# UART7 register map
Registers from a debugger description file.
Registers are 32-bit, access not given, no defined reset value unless marked. A register's access mark holds for its fields unless they carry their own. Addresses are absolute; registers are grouped by the start of their names; lines under a group give offsets from that group; [hi:lo] are bit positions; {n}, {i} and the like mark numbered series; 'fields as' and 'values as' point back to an identical list; <NAME> marks a mode.

## SFR
0x50003000 UART7DLL
  [7:0] DLL
0x50003000 UART7THR
  [7:0] THR
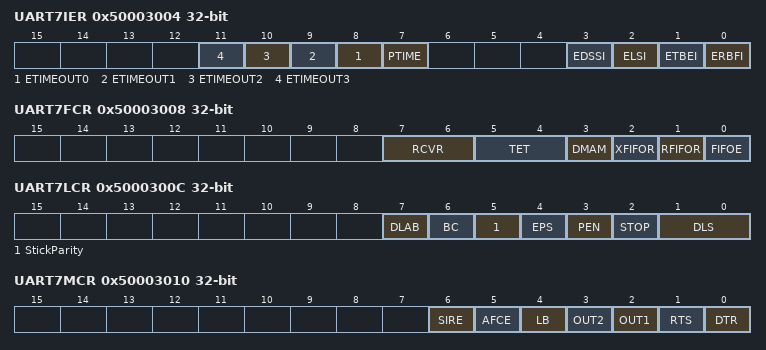
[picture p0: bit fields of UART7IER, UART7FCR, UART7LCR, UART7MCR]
0x50003004 UART7IER
  [n+8] ETIMEOUT{n} (n=0..3), [7] PTIME, [3] EDSSI, [2] ELSI, [1] ETBEI, [0] ERBFI
0x50003004 UART7DLH
  [7:0] DLH
0x50003008 UART7FCR
  [7:6] RCVR, [5:4] TET, [3] DMAM, [2] XFIFOR, [1] RFIFOR, [0] FIFOE
0x5000300C UART7LCR
  [7] DLAB, [6] BC, [5] StickParity, [4] EPS, [3] PEN, [2] STOP, [1:0] DLS
0x50003010 UART7MCR
  [6] SIRE, [5] AFCE, [4] LB, [3] OUT2, [2] OUT1, [1] RTS, [0] DTR
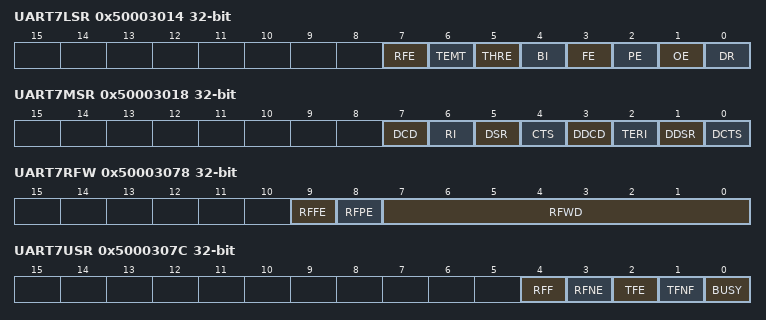
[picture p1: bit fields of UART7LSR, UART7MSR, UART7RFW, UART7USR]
0x50003014 UART7LSR ro
  [7] RFE, [6] TEMT, [5] THRE, [4] BI, [3] FE, [2] PE, [1] OE, [0] DR
0x50003018 UART7MSR ro
  [7] DCD, [6] RI, [5] DSR, [4] CTS, [3] DDCD, [2] TERI, [1] DDSR, [0] DCTS
0x5000301C UART7SCR
  [7:0] SCR
0x50003030 UART7STHR
  [7:0] STHR
0x50003070 UART7FAR
  [0] FAR
0x50003074 UART7TFR ro
  [7:0] TFR
0x50003078 UART7RFW
  [9] RFFE, [8] RFPE, [7:0] RFWD
0x5000307C UART7USR ro
  [4] RFF, [3] RFNE, [2] TFE, [1] TFNF, [0] BUSY
0x50003080 UART7TFL ro
  [4:0] TFL
0x50003084 UART7RFL ro
  [4:0] RFL
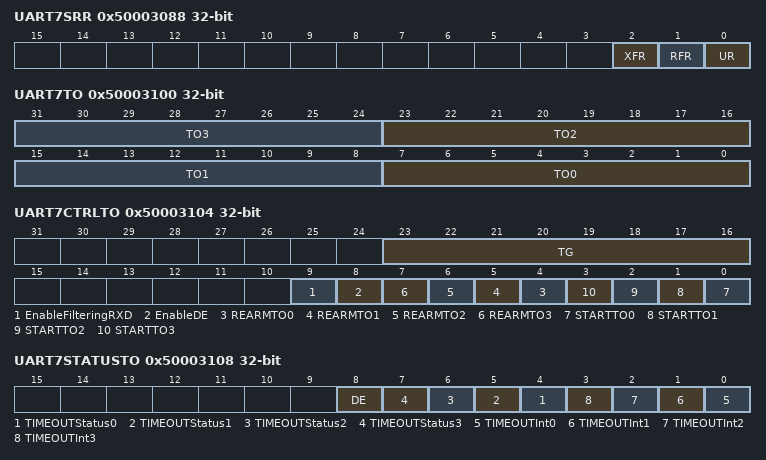
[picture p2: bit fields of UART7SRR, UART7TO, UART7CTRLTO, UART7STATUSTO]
0x50003088 UART7SRR
  [2] XFR, [1] RFR, [0] UR
0x5000308C UART7SRTS
  [0] SRTS
0x50003090 UART7SBCR
  [0] SBCR
0x50003098 UART7SFE
  [0] SFE
0x5000309C UART7SRT
  [1:0] SRCVR
0x500030A0 UART7STET
  [1:0] STET
0x500030A4 UART7HTX
  [0] HTX
0x500030A8 UART7DMASA
  [0] DMASA
0x500030F8 UART7UCV ro
  [31:0] Version
0x500030FC UART7CTR ro
  [31:0] ID
0x50003100 UART7TO
  [8n+7:8n] TO{n} (n=0..3)
0x50003104 UART7CTRLTO
  [23:16] TG, [9] EnableFilteringRXD, [8] EnableDE, [n+4] REARMTO{n} (n=0..3), [n] STARTTO{n} (n=0..3)
0x50003108 UART7STATUSTO
  [8] DE, [n+4] TIMEOUTStatus{n} (n=0..3), [n] TIMEOUTInt{n} (n=0..3)
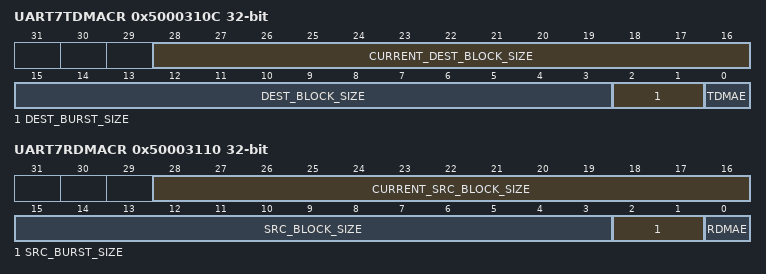
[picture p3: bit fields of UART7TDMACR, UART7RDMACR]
0x5000310C UART7TDMACR
  [28:16] CURRENT_DEST_BLOCK_SIZE, [15:3] DEST_BLOCK_SIZE, [2:1] DEST_BURST_SIZE, [0] TDMAE
0x50003110 UART7RDMACR
  [28:16] CURRENT_SRC_BLOCK_SIZE, [15:3] SRC_BLOCK_SIZE, [2:1] SRC_BURST_SIZE, [0] RDMAE
